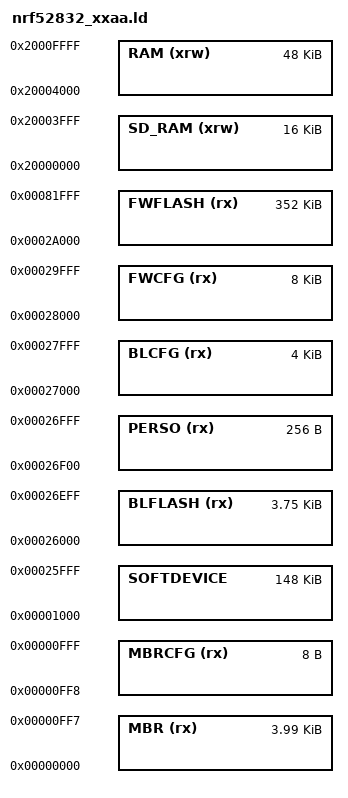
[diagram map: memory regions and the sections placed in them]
MEMORY {
    SD_RAM(xrw) : ORIGIN = 0x20000000, LENGTH = 16K
    RAM(xrw)    : ORIGIN = 0x20000000+16K, LENGTH = 64K-16K

    MBR(rx)     : ORIGIN = 0x00000000, LENGTH = 4K-8
    MBRCFG(rx)  : ORIGIN = 0x00000FF8, LENGTH = 8

    SOFTDEVICE  : ORIGIN = 0x00001000, LENGTH = 148K

    BLFLASH(rx) : ORIGIN = ORIGIN(SOFTDEVICE)+LENGTH(SOFTDEVICE), LENGTH = 4K-256
    PERSO(rx)   : ORIGIN = ORIGIN(BLFLASH)+LENGTH(BLFLASH), LENGTH = 256
    BLCFG(rx)   : ORIGIN = ORIGIN(PERSO)+LENGTH(PERSO), LENGTH = 4K

    FWCFG(rx)   : ORIGIN = ORIGIN(BLCFG)+LENGTH(BLCFG), LENGTH = 8K
    FWFLASH(rx) : ORIGIN = ORIGIN(FWCFG)+LENGTH(FWCFG), LENGTH = 512K-ORIGIN(FWCFG)
}
